# STM32H7R register map
File version: 1.4
CPU: CM7 r0p1, little endian, MPU, FPU, 4 interrupt priority bits
Registers are 32-bit, read-write, reset 0x0 unless marked. A register's access mark holds for its fields unless they carry their own. Offsets are from the block's base; [hi:lo] are bit positions; {n}, {i} and the like mark numbered series; 'fields as' and 'values as' point back to an identical list; <NAME> marks a mode.

## RCC (part 1 of 2) — RCC register block
Base 0x58024400
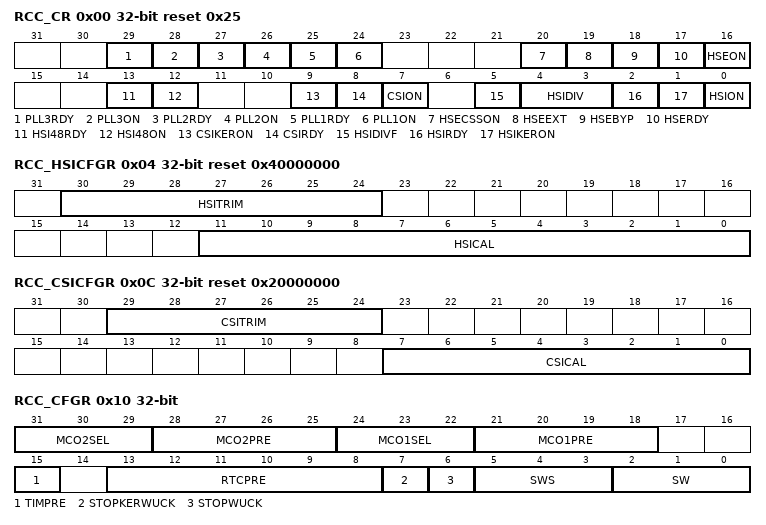
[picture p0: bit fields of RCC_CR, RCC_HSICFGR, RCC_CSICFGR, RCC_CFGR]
0x00 RCC_CR reset 0x25 — RCC source control register
  [29] PLL3RDY ro — PLL3 clock ready flag
    0=PLL3 unlocked (default after reset); 1=PLL3 locked
  [28] PLL3ON — PLL3 enable
    0=PLL3 OFF (default after reset); 1=PLL3 ON
  [27] PLL2RDY ro — PLL2 clock ready flag
    0=PLL2 unlocked (default after reset); 1=PLL2 locked
  [26] PLL2ON — PLL2 enable
    0=PLL2 OFF (default after reset); 1=PLL2 ON
  [25] PLL1RDY ro — PLL1 clock ready flag
    0=PLL1 unlocked (default after reset); 1=PLL1 locked
  [24] PLL1ON — PLL1 enable
    0=PLL1 OFF (default after reset); 1=PLL1 ON
  [20] HSECSSON — HSE clock security system enable
    0=CSS on HSE OFF (clock detector OFF) (default after reset); 1=CSS on HSE ON (clock detector ON if the HSE oscillator is stable, OFF if not)
  [19] HSEEXT — external high speed clock type in Bypass mode
    0=HSE in analog mode (default after reset); 1=HSE in digital mode
  [18] HSEBYP — HSE clock bypass
    0=HSE oscillator not bypassed (default after reset); 1=HSE oscillator bypassed with an external clock
  [17] HSERDY ro — HSE clock ready flag
    0=HSE clock is not ready (default after reset); 1=HSE clock is ready
  [16] HSEON — HSE clock enable
    0=HSE is OFF (default after reset); 1=HSE is ON
  [13] HSI48RDY ro — HSI48 clock ready flag
    0=HSI48 clock is not ready (default after reset); 1=HSI48 clock is ready
  [12] HSI48ON — HSI48 clock enable
    0=HSI48 is OFF (default after reset); 1=HSI48 is ON
  [9] CSIKERON — CSI clock enable in Stop mode
    0=no effect on CSI (default after reset); 1=CSI is forced to ON even in Stop mode
  [8] CSIRDY ro — CSI clock ready flag
    0=CSI clock is not ready (default after reset); 1=CSI clock is ready
  [7] CSION — CSI clock enable
    0=CSI is OFF (default after reset); 1=CSI is ON
  [5] HSIDIVF ro — HSI divider flag
    0=new division ratio not yet propagated to hsi(_ker)_ck (default after reset); 1=hsi(_ker)_ck clock frequency reflects the new HSIDIV value (default register value when the
  [4:3] HSIDIV — HSI clock divider
    0=division by 1, hsi(_ker)_ck = 64 MHz (default after reset); 1=division by 2, hsi(_ker)_ck = 32 MHz; 2=division by 4, hsi(_ker)_ck = 16 MHz; 3=division by 8, hsi(_ker)_ck = 8 MHz
  [2] HSIRDY ro — HSI clock ready flag
    0=HSI clock is not ready (default after reset); 1=HSI clock is ready
  [1] HSIKERON — HSI clock enable in Stop mode
    0=no effect on HSI (default after reset); 1=HSI is forced to ON even in Stop mode
  [0] HSION — HSI clock enable
    0=HSI is OFF; 1=HSI is ON (default after reset)
0x04 RCC_HSICFGR reset 0x40000000 (reset mask 0xFFFFF000) — RCC HSI calibration register
  [30:24] HSITRIM — HSI clock trimming
  [11:0] HSICAL ro — HSI clock calibration
0x08 RCC_CRRCR ro (reset mask 0xFFFFF000) — RCC clock recovery RC register
  [9:0] HSI48CAL — Internal RC 48 MHz clock calibration
0x0C RCC_CSICFGR reset 0x20000000 (reset mask 0xFFFFF000) — RCC CSI calibration register
  [29:24] CSITRIM — CSI clock trimming
  [7:0] CSICAL ro — CSI clock calibration
0x10 RCC_CFGR — RCC clock configuration register
  [31:29] MCO2SEL — microcontroller clock output 2
    0=system clock selected (sys_ck) (default after reset); 1=PLL2 oscillator clock selected (pll2_p_ck); 2=HSE clock selected (hse_ck); 3=PLL1 clock selected (pll1_p_ck); 4=CSI clock selected (csi_ck); 5=LSI clock selected (lsi_ck)
  [28:25] MCO2PRE — MCO2 prescaler
    0=prescaler disabled (default after reset); 1=division by 1 (bypass); 2=division by 2; 3=division by 3; 4=division by 4; 15=division by 15
  [24:22] MCO1SEL — Microcontroller clock output 1
    0=HSI clock selected (hsi_ck) (default after reset); 1=LSE oscillator clock selected (lse_ck); 2=HSE clock selected (hse_ck); 3=PLL1 clock selected (pll1_q_ck); 4=HSI48 clock selected (hsi48_ck)
  [21:18] MCO1PRE — MCO1 prescaler
    values as MCO2PRE
  [15] TIMPRE — timers clocks prescaler selection
    0=The timers kernel clock is equal to rcc_hclk1 if CDPPREx is corresponding to division by 1 or 2, else it is equal to 2 x F<sub>rcc_pclkx_d2 </sub>(default after reset); 1=The timers kernel clock is equal to rcc_hclk1 if CDPPREx is corresponding to division by 1, 2
  [13:8] RTCPRE — HSE division factor for RTC clock
    0=no clock (default after reset); 1=no clock; 2=HSE/2; 3=HSE/3; 4=HSE/4; 62=HSE/62; 63=HSE/63
  [7] STOPKERWUCK — kernel clock selection after a wake up from system Stop
    0=HSI selected as wake up clock from system Stop (default after reset); 1=CSI selected as wake up clock from system Stop
  [6] STOPWUCK — system clock selection after a wake up from system Stop
    values as STOPKERWUCK
  [5:3] SWS ro — system clock switch status
    0=HSI used as system clock (hsi_ck) (default after reset); 1=CSI used as system clock (csi_ck); 2=HSE used as system clock (hse_ck); 3=PLL1 used as system clock (pll1_p_ck)
  [2:0] SW — system clock switch
    0=HSI selected as system clock (hsi_ck) (default after reset); 1=CSI selected as system clock (csi_ck); 2=HSE selected as system clock (hse_ck); 3=PLL1 selected as system clock (pll1_p_ck)
0x18 RCC_CDCFGR — RCC CPU domain clock configuration register
  [3:0] CPRE — CPU domain core prescaler
    8=sys_ck divided by 2; 9=sys_ck divided by 4; 10=sys_ck divided by 8; 11=sys_ck divided by 16; 12=sys_ck divided by 64; 13=sys_ck divided by 128; 14=sys_ck divided by 256; 15=sys_ck divided by 512
0x1C RCC_BMCFGR — RCC AHB clock configuration register
  [3:0] BMPRE — Bus matrix clock prescaler
    8=sys_bus_ck = sys_cpu_ck / 2; 9=sys_bus_ck= sys_cpu_ck / 4; 10=sys_bus_ck = sys_cpu_ck / 8; 11=sys_bus_ck = sys_cpu_ck / 16; 12=sys_bus_ck = sys_cpu_ck / 64; 13=sys_bus_ck = sys_cpu_ck / 128; 14=sys_bus_ck = sys_cpu_ck / 256; 15=sys_bus_ck = sys_cpu_ck / 512
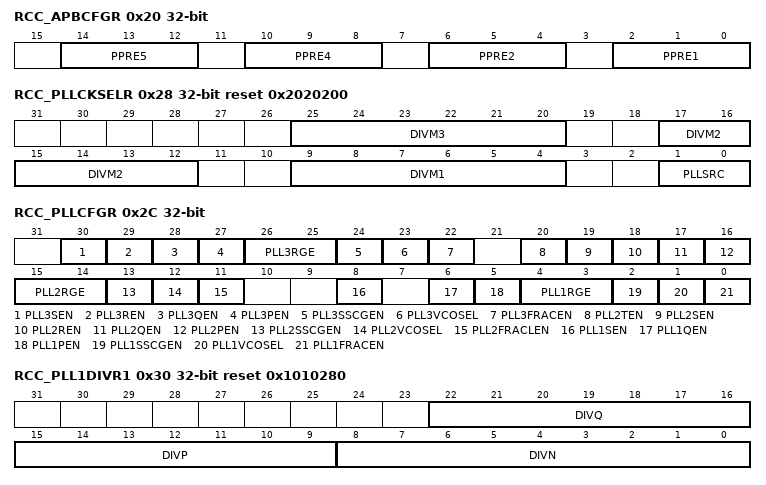
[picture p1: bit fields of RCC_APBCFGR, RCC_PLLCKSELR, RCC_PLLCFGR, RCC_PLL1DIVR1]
0x20 RCC_APBCFGR — RCC APB clocks configuration register
  [14:12] PPRE5 — CPU domain APB5 prescaler
    4=rcc_pclk5 = sys_bus_ck / 2; 5=rcc_pclk5 = sys_bus_ck / 4; 6=rcc_pclk5 = sys_bus_ck / 8; 7=rcc_pclk5 = sys_bus_ck / 16
  [10:8] PPRE4 — CPU domain APB4 prescaler
    4=rcc_pclk4 = sys_bus_ck / 2; 5=rcc_pclk4 = sys_bus_ck / 4; 6=rcc_pclk4 = sys_bus_ck / 8; 7=rcc_pclk4 = sys_bus_ck / 16
  [6:4] PPRE2 — CPU domain APB2 prescaler
    4=rcc_pclk2 = sys_bus_ck / 2; 5=rcc_pclk2 = sys_bus_ck / 4; 6=rcc_pclk2 = sys_bus_ck / 8; 7=rcc_pclk2 = sys_bus_ck / 16
  [2:0] PPRE1 — CPU domain APB1 prescaler
    4=rcc_pclk1 = sys_bus_ck / 2; 5=rcc_pclk1 = sys_bus_ck / 4; 6=rcc_pclk1 = sys_bus_ck / 8; 7=rcc_pclk1 = sys_bus_ck / 16
0x28 RCC_PLLCKSELR reset 0x2020200 — RCC PLLs clock source selection register
  [25:20] DIVM3 — prescaler for PLL3
    0=prescaler disabled; 1=division by 1 (bypass); 2=division by 2; 3=division by 3; 32=division by 32 (default after reset); 63=division by 63
  [17:12] DIVM2 — prescaler for PLL2
    values as DIVM3
  [9:4] DIVM1 — prescaler for PLL1
    values as DIVM3
  [1:0] PLLSRC — DIVMx and PLLs clock source selection
    0=HSI selected as PLL clock (hsi_ck) (default after reset); 1=CSI selected as PLL clock (csi_ck); 2=HSE selected as PLL clock (hse_ck); 3=no clock send to DIVMx divider and PLLs
0x2C RCC_PLLCFGR — RCC PLLs configuration register
  [30] PLL3SEN — PLL3 DIVS divider output enable
    0=pll3_s_ck output disabled (default after reset); 1=pll3_s_ck output enabled
  [29] PLL3REN — PLL3 DIVR divider output enable
    0=pll3_r_ck output disabled (default after reset); 1=pll3_r_ck output enabled
  [28] PLL3QEN — PLL3 DIVQ divider output enable
    0=pll3_q_ck output disabled (default after reset); 1=pll3_q_ck output enabled
  [27] PLL3PEN — PLL3 DIVP divider output enable
    0=pll3_p_ck output disabled (default after reset); 1=pll3_p_ck output enabled
  [26:25] PLL3RGE — PLL3 input frequency range
    0=PLL3 input (ref3_ck) clock range frequency between 1 and 2 MHz (default after reset); 1=PLL3 input (ref3_ck) clock range frequency between 2 and 4 MHz; 2=PLL3 input (ref3_ck) clock range frequency between 4 and 8 MHz; 3=PLL3 input (ref3_ck) clock range frequency between 8 and 16 MHz
  [24] PLL3SSCGEN — PLL3 SSCG enable
    0=SSCG disabled (default after reset); 1=SSCG enabled
  [23] PLL3VCOSEL — PLL3 VCO selection
    0=VCOH selected (default after reset); 1=VCOL selected
  [22] PLL3FRACEN — PLL3 fractional latch enable
  [20] PLL2TEN — PLL2 DIVT divider output enable
    0=pll2_t_ck output disabled (default after reset); 1=pll2_t_ck output enabled
  [19] PLL2SEN — PLL2 DIVS divider output enable
    0=pll2_s_ck output disabled (default after reset); 1=pll2_s_ck output enabled
  [18] PLL2REN — PLL2 DIVR divider output enable
    0=pll2_r_ck output disabled (default after reset); 1=pll2_r_ck output enabled
  [17] PLL2QEN — PLL2 DIVQ divider output enable
    0=pll2_q_ck output disabled (default after reset); 1=pll2_q_ck output enabled
  [16] PLL2PEN — PLL2 DIVP divider output enable
    0=pll2_p_ck output disabled (default after reset); 1=pll2_p_ck output enabled
  [15:14] PLL2RGE — PLL2 input frequency range
    0=PLL3 input (ref2_ck) clock range frequency between 1 and 2 MHz (default after reset); 1=PLL3 input (ref2_ck) clock range frequency between 2 and 4 MHz; 2=PLL3 input (ref2_ck) clock range frequency between 4 and 8 MHz; 3=PLL3 input (ref2_ck) clock range frequency between 8 and 16 MHz
  [13] PLL2SSCGEN — PLL2 SSCG enable
    0=SSCG disabled (default after reset); 1=SSCG enabled
  [12] PLL2VCOSEL — PLL2 VCO selection
    0=VCOH selected (default after reset); 1=VCOL selected
  [11] PLL2FRACLEN — PLL2 fractional latch enable
  [8] PLL1SEN — PLL1 DIVS divider output enable
    0=pll1_s_ck output disabled (default after reset); 1=pll1_s_ck output enabled
  [6] PLL1QEN — PLL1 DIVQ divider output enable
    0=pll1_q_ck output disabled (default after reset); 1=pll1_q_ck output enabled
  [5] PLL1PEN — PLL1 DIVP divider output enable
    0=pll1_p_ck output disabled (default after reset); 1=pll1_p_ck output enabled
  [4:3] PLL1RGE — PLL1 input frequency range
    0=PLL1 input (ref1_ck) clock range frequency between 1 and 2 MHz (default after reset); 1=PLL1 input (ref1_ck) clock range frequency between 2 and 4 MHz; 2=PLL1 input (ref1_ck) clock range frequency between 4 and 8 MHz; 3=PLL1 input (ref1_ck) clock range frequency between 8 and 16 MHz
  [2] PLL1SSCGEN — PLL1 SSCG enable
    0=SSCG disabled (default after reset); 1=SSCG enabled
  [1] PLL1VCOSEL — PLL1 VCO selection
    0=VCOH selected (default after reset); 1=VCOL selected
  [0] PLL1FRACEN — PLL1 fractional latch enable
0x30 RCC_PLL1DIVR1 reset 0x1010280 — RCC PLL1 dividers configuration register 1
  [22:16] DIVQ — PLL1 DIVQ division factor
    0=pll1_q_ck = vco1_ck; 1=pll1_q_ck = vco1_ck / 2 (default after reset); 2=pll1_q_ck = vco1_ck / 3; 3=pll1_q_ck = vco1_ck / 4; 127=pll1_q_ck = vco1_ck / 128
  [15:9] DIVP — PLL1 DIVP division factor
    0=pll1_p_ck = vco1_ck; 1=pll1_p_ck = vco1_ck / 2 (default after reset); 2=not allowed; 3=pll1_p_ck = vco1_ck / 4; 127=pll1_p_ck = vco1_ck / 128
  [8:0] DIVN — multiplication factor for PLL1 VCO
    6=wrong configuration; 7=DIVN = 8; 128=DIVN = 129 (default after reset); 0x1A3=DIVN = 420
{0x2C+8i} RCC_PLL{i}FRACR (i=1..3) — RCC PLL{i} fractional divider register
  [15:3] FRACN — fractional part of the multiplication factor for PLL{i} VCO
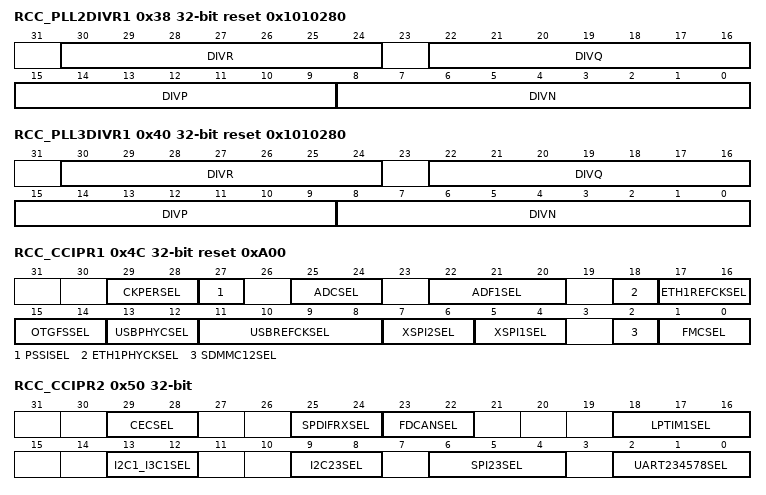
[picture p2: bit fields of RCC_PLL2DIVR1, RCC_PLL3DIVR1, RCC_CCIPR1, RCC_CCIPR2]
0x38 RCC_PLL2DIVR1 reset 0x1010280 — RCC PLL2 dividers configuration register 1
  [30:24] DIVR — PLL2 DIVR division factor
    0=pll2_r_ck = vco2_ck; 1=pll2_r_ck = vco2_ck / 2 (default after reset); 2=pll2_r_ck = vco2_ck / 3; 3=pll2_r_ck = vco2_ck / 4; 127=pll2_r_ck = vco2_ck / 128
  [22:16] DIVQ — PLL2 DIVQ division factor
    0=pll2_q_ck = vco2_ck; 1=pll2_q_ck = vco2_ck / 2 (default after reset); 2=pll2_q_ck = vco2_ck / 3; 3=pll2_q_ck = vco2_ck / 4; 127=pll2_q_ck = vco2_ck / 128
  [15:9] DIVP — PLL2 DIVP division factor
    0=pll2_p_ck = vco2_ck; 1=pll2_p_ck = vco2_ck / 2 (default after reset); 2=pll2_p_ck = vco2_ck / 3; 3=pll2_p_ck = vco2_ck / 4; 127=pll2_p_ck = vco2_ck / 128
  [8:0] DIVN — multiplication factor for PLL2 VCO
    values as RCC_PLL1DIVR1.DIVN
0x40 RCC_PLL3DIVR1 reset 0x1010280 — RCC PLL3 dividers configuration register 1
  [30:24] DIVR — PLL3 DIVR division factor
    0=pll3_r_ck = vco3_ck; 1=pll3_r_ck = vco3_ck / 2 (default after reset); 2=pll3_r_ck = vco3_ck / 3; 3=pll3_r_ck = vco3_ck / 4; 127=pll3_r_ck = vco3_ck / 128
  [22:16] DIVQ — PLL3 DIVQ division factor
    0=pll3_q_ck = vco3_ck; 1=pll3_q_ck = vco3_ck / 2 (default after reset); 2=pll3_q_ck = vco3_ck / 3; 3=pll3_q_ck = vco3_ck / 4; 127=pll3_q_ck = vco3_ck / 128
  [15:9] DIVP — PLL3 DIVP division factor
    0=pll3_p_ck = vco3_ck; 1=pll3_p_ck = vco3_ck / 2 (default after reset); 2=pll3_p_ck = vco3_ck / 3; 3=pll3_p_ck = vco3_ck / 4; 127=pll3_p_ck = vco3_ck / 128
  [8:0] DIVN — Multiplication factor for PLL3 VCO
    values as RCC_PLL1DIVR1.DIVN
0x4C RCC_CCIPR1 reset 0xA00 — RCC AHB peripheral kernel clock selection register
  [29:28] CKPERSEL — per_ck clock source selection
    0=hsi_ker_ck selected as per_ck clock (default after reset); 1=csi_ker_ck selected as per_ck clock; 2=hse_ker_ck selected as per_ck clock
  [27] PSSISEL — PSSI kernel clock source selection
    0=pll3_r_ck selected as kernel peripheral clock (default after reset); 1=per_ck selected as kernel peripheral clock
  [25:24] ADCSEL — SAR ADC kernel clock source selection
    0=pll2_p_ck selected as kernel peripheral clock (default after reset); 1=pll3_r_ck selected as kernel peripheral clock; 2=per_ck selected as kernel peripheral clock
  [22:20] ADF1SEL — ADF kernel clock source selection
    0=hclk1 selected as ADF kernel clock (default after reset); 1=pll2_p_ck selected as ADF kernel clock
  [18] ETH1PHYCKSEL — Clock source selection for external Ethernet PHY
    0=hse_ker_ck selected as clock source (default after reset); 1=pll3_s_ck selected clock source
  [17:16] ETH1REFCKSEL — Ethernet reference clock source selection
    0=PAD ETH_RMII_REF_CLK selected as kernel peripheral clock (default after reset); 1=hse_ker_ck selected as kernel peripheral clock; 2=eth_clk_fb selected as kernel peripheral clock
  [15:14] OTGFSSEL — OTGFS kernel clock source selection
    0=hsi48_ker_ck (default after reset); 1=pll3_q_ck; 2=hse_ker_ck; 3=clk48mohci
  [13:12] USBPHYCSEL — USBPHYC kernel clock source selection
    0=hse_ker_ck (default after reset); 1=hse_ker_ck / 2; 2=pll3_q_ck
  [11:8] USBREFCKSEL — USBPHYC kernel clock frequency selection
    3=The kernel clock frequency provided to the USBPHYC is 16 MHz; 8=The kernel clock frequency provided to the USBPHYC is 19; 9=The kernel clock frequency provided to the USBPHYC is 20MHz; 10=The kernel clock frequency provided to the USBPHYC is 24 MHz (default after reset); 14=The kernel clock frequency provided to the USBPHYC is 26 MHz; 11=The kernel clock frequency provided to the USBPHYC is 32 MHz
  [7:6] XSPI2SEL — XSPI2 kernel clock source selection
    0=hclk5 selected as kernel peripheral clock (default after reset); 1=pll2_s_ck selected as kernel peripheral clock
  [5:4] XSPI1SEL — XSPI1 kernel clock source selection
    values as XSPI2SEL
  [2] SDMMC12SEL — SDMMC1 and SDMMC2 kernel clock source selection
    0=pll2_s_ck selected as kernel peripheral clock (default after reset); 1=pll2_t_ck selected as kernel peripheral clock
  [1:0] FMCSEL — FMC kernel clock source selection
    0=hclk5 selected as kernel peripheral clock (default after reset); 1=pll1_q_ck selected as kernel peripheral clock; 2=pll2_r_ck selected as kernel peripheral clock; 3=hsi_ker_ck selected as kernel peripheral clock
0x50 RCC_CCIPR2 — RCC APB1 peripherals kernel clock selection register
  [29:28] CECSEL — HDMI-CEC kernel clock source selection
    0=lse_ck selected as kernel clock (default after reset); 1=lsi_ck selected as kernel clock; 2=csi_ker_ck divided by 122 selected as kernel clock
  [25:24] SPDIFRXSEL — SPDIFRX kernel clock source selection
    0=pll1_q_ck selected as SPDIFRX kernel clock (default after reset); 1=pll2_r_ck selected as SPDIFRX kernel clock; 2=pll3_r_ck selected as SPDIFRX kernel clock; 3=hsi_ker_ck selected as SPDIFRX kernel clock
  [23:22] FDCANSEL — FDCAN kernel clock source selection
    0=hse_ker_ck selected as FDCAN kernel clock (default after reset); 1=pll1_q_ck selected as FDCAN kernel clock; 2=pll2_p_ck selected as FDCAN kernel clock
  [18:16] LPTIM1SEL — LPTIM1 kernel clock source selection
    0=pclk1 selected as kernel peripheral clock (default after reset); 1=pll2_p_ck selected as kernel peripheral clock; 2=pll3_r_ck selected as kernel peripheral clock; 3=lse_ck selected as kernel peripheral clock; 4=lsi_ck selected as kernel peripheral clock; 5=per_ck selected as kernel peripheral clock
  [13:12] I2C1_I3C1SEL — I2C1 or I3C1 kernel clock source selection
    0=pclk1 selected as kernel peripheral clock (default after reset); 1=pll3_r_ck selected as kernel peripheral clock; 2=hsi_ker_ck selected as kernel peripheral clock; 3=csi_ker_ck selected as kernel peripheral clock
  [9:8] I2C23SEL — I2C2, I2C3 kernel clock source selection
    0=pclk1 selected as kernel clock (default after reset); 1=pll3_r_ck selected as kernel clock; 2=hsi_ker_ck selected as kernel clock; 3=csi_ker_ck selected as kernel clock
  [6:4] SPI23SEL — SPI/I2S2 and SPI/I2S3 kernel clock source selection
    0=pll1_q_ck selected as kernel clock (default after reset); 1=pll2_p_ck selected as kernel clock; 2=pll3_p_ck selected as kernel clock; 3=I2S_CKIN selected as kernel clock; 4=per_ck selected as kernel clock
  [2:0] UART234578SEL — USART2,3, UART4,5,7,8 (APB1) kernel clock source selection
    0=pclk1 selected as kernel clock (default after reset); 1=pll2_q_ck selected as kernel clock; 2=pll3_q_ck selected as kernel clock; 3=hsi_ker_ck selected as kernel clock; 4=csi_ker_ck selected as kernel clock; 5=lse_ck selected as kernel clock
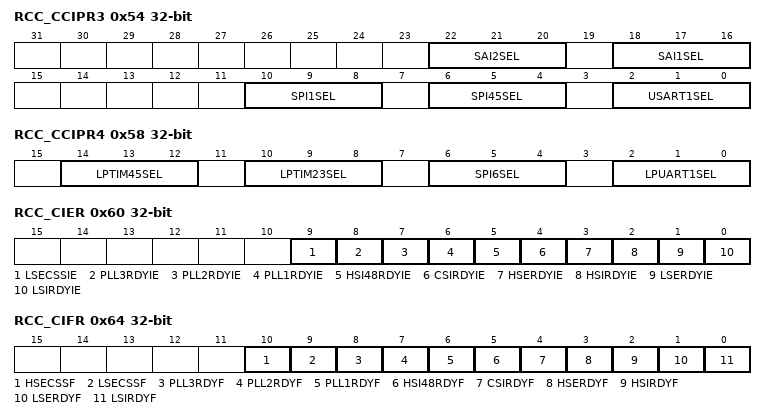
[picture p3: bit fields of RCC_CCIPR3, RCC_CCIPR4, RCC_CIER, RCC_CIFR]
0x54 RCC_CCIPR3 — RCC APB2 peripherals kernel clock selection register
  [22:20] SAI2SEL — SAI2 kernel clock source selection
    0=pll1_q_ck selected as SAI2 kernel clock (default after reset); 1=pll2_p_ck selected as SAI2 kernel clock; 2=pll3_p_ck selected as SAI2 kernel clock; 3=I2S_CKIN selected as SAI2 kernel clock; 4=per_ck selected as SAI2 kernel clock; 5=spdifrx_symb_ck selected as SAI2 kernel clock
  [18:16] SAI1SEL — SAI1 kernel clock source selection
    0=pll1_q_ck selected as SAI1 kernel clock (default after reset); 1=pll2_p_ck selected as SAI1 kernel clock; 2=pll3_p_ck selected as SAI1 kernel clock; 3=I2S_CKIN selected as SAI1 kernel clock; 4=per_ck selected as SAI1 kernel clock
  [10:8] SPI1SEL — SPI/I2S1 kernel clock source selection
    0=pll1_q_ck selected as SPI/I2S1 and 7 kernel clock (default after reset); 1=pll2_p_ck selected as SPI/I2S1 and 7 kernel clock; 2=pll3_p_ck selected as SPI/I2S1 and 7 kernel clock; 3=I2S_CKIN selected as SPI/I2S1 and 7 kernel clock; 4=per_ck selected as SPI/I2S1,and 7 kernel clock
  [6:4] SPI45SEL — SPI4 and 5 kernel clock source selection
    0=pclk2 selected as kernel clock (default after reset); 1=pll2_q_ck is selected as kernel clock; 2=pll3_q_ck is selected as kernel clock; 3=hsi_ker_ck is selected as kernel clock; 4=csi_ker_ck is selected as kernel clock; 5=hse_ker_ck is selected as kernel clock
  [2:0] USART1SEL — USART1 kernel clock source selection
    0=pclk2 selected as kernel clock (default after reset); 1=pll2_q_ck selected as kernel clock; 2=pll3_q_ck selected as kernel clock; 3=hsi_ker_ck selected as kernel clock; 4=csi_ker_ck selected as kernel clock; 5=lse_ck selected as kernel clock
0x58 RCC_CCIPR4 — RCC APB4,5 peripherals kernel clock selection register
  [14:12] LPTIM45SEL — LPTIM4, and LPTIM5 kernel clock source selection
    0=pclk4 selected as kernel peripheral clock (default after reset); 1=pll2_p_ck selected as kernel peripheral clock; 2=pll3_r_ck selected as kernel peripheral clock; 3=lse_ck selected as kernel peripheral clock; 4=lsi_ck selected as kernel peripheral clock; 5=per_ck selected as kernel peripheral clock
  [10:8] LPTIM23SEL — LPTIM2 and LPTIM3 kernel clock source selection
    values as LPTIM45SEL
  [6:4] SPI6SEL — SPI/I2S6 kernel clock source selection
    0=pclk4 selected as kernel peripheral clock (default after reset); 1=pll2_q_ck selected as kernel peripheral clock; 2=pll3_q_ck selected as kernel peripheral clock; 3=hsi_ker_ck selected as kernel peripheral clock; 4=csi_ker_ck selected as kernel peripheral clock; 5=hse_ker_ck selected as kernel peripheral clock
  [2:0] LPUART1SEL — LPUART1 kernel clock source selection
    0=pclk4 selected as kernel peripheral clock (default after reset); 1=pll2_q_ck selected as kernel peripheral clock; 2=pll3_q_ck selected as kernel peripheral clock; 3=hsi_ker_ck selected as kernel peripheral clock; 4=csi_ker_ck selected as kernel peripheral clock; 5=lse_ck selected as kernel peripheral clock
0x60 RCC_CIER — RCC clock source interrupt enable register
  [9] LSECSSIE — LSE clock security system interrupt enable
    0=LSE CSS interrupt disabled (default after reset); 1=LSE CSS interrupt enabled
  [8] PLL3RDYIE — PLL3 ready interrupt enable
    0=PLL3 lock interrupt disabled (default after reset); 1=PLL3 lock interrupt enabled
  [7] PLL2RDYIE — PLL2 ready interrupt enable
    0=PLL2 lock interrupt disabled (default after reset); 1=PLL2 lock interrupt enabled
  [6] PLL1RDYIE — PLL1 ready interrupt enable
    0=PLL1 lock interrupt disabled (default after reset); 1=PLL1 lock interrupt enabled
  [5] HSI48RDYIE — HSI48 ready interrupt enable
    0=HSI48 ready interrupt disabled (default after reset); 1=HSI48 ready interrupt enabled
  [4] CSIRDYIE — CSI ready interrupt enable
    0=CSI ready interrupt disabled (default after reset); 1=CSI ready interrupt enabled
  [3] HSERDYIE — HSE ready interrupt enable
    0=HSE ready interrupt disabled (default after reset); 1=HSE ready interrupt enabled
  [2] HSIRDYIE — HSI ready interrupt enable
    0=HSI ready interrupt disabled (default after reset); 1=HSI ready interrupt enabled
  [1] LSERDYIE — LSE ready interrupt enable
    0=LSE ready interrupt disabled (default after reset); 1=LSE ready interrupt enabled
  [0] LSIRDYIE — LSI ready interrupt enable
    0=LSI ready interrupt disabled (default after reset); 1=LSI ready interrupt enabled
0x64 RCC_CIFR ro — RCC clock source interrupt flag register
  [10] HSECSSF — HSE clock security system interrupt flag
    0=no clock security interrupt caused by HSE clock failure (default after reset); 1=clock security interrupt caused by HSE clock failure
  [9] LSECSSF — LSE clock security system interrupt flag
    0=no failure detected on the external 32 kHz oscillator (default after reset); 1=failure detected on the external 32 kHz oscillator
  [8] PLL3RDYF — PLL3 ready interrupt flag
    0=no clock ready interrupt caused by PLL3 lock (default after reset); 1=clock ready interrupt caused by PLL3 lock
  [7] PLL2RDYF — PLL2 ready interrupt flag
    0=no clock ready interrupt caused by PLL2 lock (default after reset); 1=clock ready interrupt caused by PLL2 lock
  [6] PLL1RDYF — PLL1 ready interrupt flag
    0=no clock ready interrupt caused by PLL1 lock (default after reset); 1=clock ready interrupt caused by PLL1 lock
  [5] HSI48RDYF — HSI48 ready interrupt flag
    0=no clock ready interrupt caused by the HSI48 oscillator (default after reset); 1=clock ready interrupt caused by the HSI48 oscillator
  [4] CSIRDYF — CSI ready interrupt flag
    0=no clock ready interrupt caused by the CSI (default after reset); 1=clock ready interrupt caused by the CSI
  [3] HSERDYF — HSE ready interrupt flag
    0=no clock ready interrupt caused by the HSE (default after reset); 1=clock ready interrupt caused by the HSE
  [2] HSIRDYF — HSI ready interrupt flag
    0=no clock ready interrupt caused by the HSI (default after reset); 1=clock ready interrupt caused by the HSI
  [1] LSERDYF — LSE ready interrupt flag
    0=no clock ready interrupt caused by the LSE (default after reset); 1=clock ready interrupt caused by the LSE
  [0] LSIRDYF — LSI ready interrupt flag
    0=no clock ready interrupt caused by the LSI (default after reset); 1=clock ready interrupt caused by the LSI
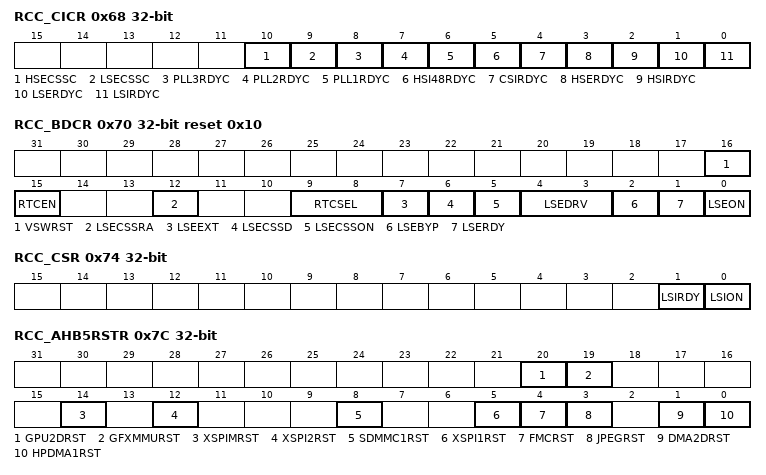
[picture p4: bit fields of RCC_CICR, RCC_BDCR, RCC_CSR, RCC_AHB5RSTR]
0x68 RCC_CICR — RCC clock source interrupt clear register
  [10] HSECSSC — HSE clock security system interrupt clear
    0=HSECSSF no effect (default after reset); 1=HSECSSF cleared
  [9] LSECSSC — LSE clock security system interrupt clear
    0=LSECSSF no effect (default after reset); 1=LSECSSF cleared
  [8] PLL3RDYC — PLL3 ready interrupt clear
    0=PLL3RDYF no effect (default after reset); 1=PLL3RDYF cleared
  [7] PLL2RDYC — PLL2 ready interrupt clear
    0=PLL2RDYF no effect (default after reset); 1=PLL2RDYF cleared
  [6] PLL1RDYC — PLL1 ready interrupt clear
    0=PLL1RDYF no effect (default after reset); 1=PLL1RDYF cleared
  [5] HSI48RDYC — HSI48 ready interrupt clear
    0=HSI48RDYF no effect (default after reset); 1=HSI48RDYF cleared
  [4] CSIRDYC — CSI ready interrupt clear
    0=CSIRDYF no effect (default after reset); 1=CSIRDYF cleared
  [3] HSERDYC — HSE ready interrupt clear
    0=HSERDYF no effect (default after reset); 1=HSERDYF cleared
  [2] HSIRDYC — HSI ready interrupt clear
    0=HSIRDYF no effect (default after reset); 1=HSIRDYF cleared
  [1] LSERDYC — LSE ready interrupt clear
    0=LSERDYF no effect (default after reset); 1=LSERDYF cleared
  [0] LSIRDYC — LSI ready interrupt clear
    0=LSIRDYF no effect (default after reset); 1=LSIRDYF cleared
0x70 RCC_BDCR rw-once reset 0x10 — RCC Backup domain control register
  [16] VSWRST rw — VSwitch domain software reset
    0=reset not activated (default after Backup domain reset); 1=generates a reset pulse, resetting the entire VSW domain
  [15] RTCEN rw — RTC clock enable
    0=rtc_ck disabled (default after Backup domain reset); 1=rtc_ck enabled
  [12] LSECSSRA rw — Re-Arm the LSECSS function
    0=Writing 0 has no effect (default after Backup domain reset); 1=Writing 1 generates a re-arm pulse for the LSECSS function
  [9:8] RTCSEL — RTC clock source selection
    0=no clock (default after Backup domain reset); 1=LSE selected as RTC clock; 2=LSI selected as RTC clock; 3=HSE divided by RTCPRE value selected as RTC clock
  [7] LSEEXT rw — low-speed external clock type in Bypass mode
    0=LSE in analog mode (default after Backup domain reset); 1=LSE in digital mode (do not use if RTC is active)
  [6] LSECSSD ro — LSE clock security system failure detection
    0=no failure detected on 32 kHz oscillator (default after Backup domain reset); 1=failure detected on 32 kHz oscillator
  [5] LSECSSON rw — LSE clock security system enable
    0=CSS on 32 kHz oscillator OFF (default after Backup domain reset); 1=CSS on 32 kHz oscillator ON
  [4:3] LSEDRV rw — LSE oscillator driving capability
    0=lowest drive; 1=medium-low drive; 2=medium-high drive (default after backup domain if LSEON=0); 3=highest drive
  [2] LSEBYP rw — LSE oscillator bypass
    0=LSE oscillator not bypassed (default after Backup domain reset); 1=LSE oscillator bypassed
  [1] LSERDY ro — LSE oscillator ready
    0=LSE oscillator not ready (default after Backup domain reset); 1=LSE oscillator ready
  [0] LSEON rw — LSE oscillator enabled
    0=LSE oscillator OFF (default after Backup domain reset); 1=LSE oscillator ON
0x74 RCC_CSR — RCC clock control and status register
  [1] LSIRDY ro — LSI oscillator ready
    0=LSI clock is not ready (default after reset); 1=LSI clock is ready
  [0] LSION — LSI oscillator enable
    0=LSI is OFF (default after reset); 1=LSI is ON
0x7C RCC_AHB5RSTR — RCC AHB5 peripheral reset register
  [all] fields
    0=reset is released (default after reset); 1=reset is asserted
  [20] GPU2DRST — GPU2D block reset
  [19] GFXMMURST — GFXMMU block reset
  [14] XSPIMRST — XSPIM reset
  [12] XSPI2RST — XSPI2 and MCE2 blocks reset
  [8] SDMMC1RST — SDMMC1 and DB_SDMMC1 blocks reset
  [5] XSPI1RST — XSPI1 and MCE1 blocks reset
  [4] FMCRST — FMC and MCE3 blocks reset
  [3] JPEGRST — JPEG block reset
  [1] DMA2DRST — DMA2D block reset
  [0] HPDMA1RST — HPDMA1 block reset
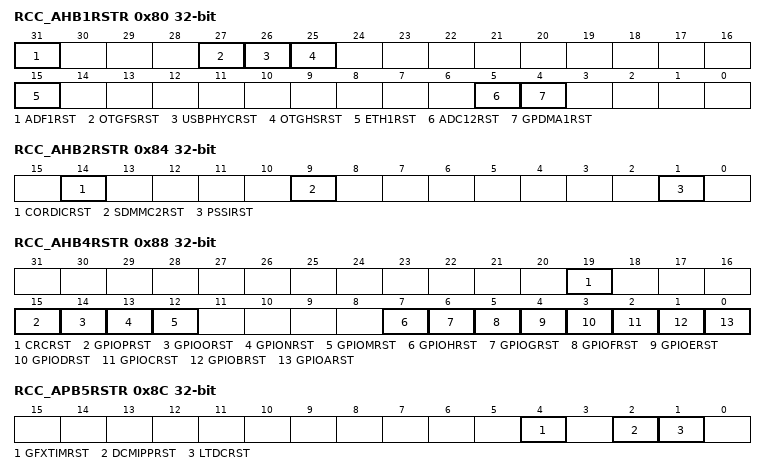
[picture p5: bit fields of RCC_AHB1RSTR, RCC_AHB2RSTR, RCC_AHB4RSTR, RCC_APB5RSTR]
0x80 RCC_AHB1RSTR — RCC AHB1 peripheral reset register
  [31] ADF1RST — ADF block reset
    0=does not reset ADF block (default after reset); 1=resets ADF block
  [27] OTGFSRST — OTGFS block reset
    0=does not reset OTGFS block (default after reset); 1=resets OTGFS block
  [26] USBPHYCRST — USBPHYC block reset
    0=does not reset USBPHYC block (default after reset); 1=resets USBPHYC block
  [25] OTGHSRST — OTGHS block reset
    0=does not reset OTGHS block (default after reset); 1=resets OTGHS block
  [15] ETH1RST — ETH1 block reset
    0=does not reset ETH1 block (default after reset); 1=resets ETH1 block
  [5] ADC12RST — ADC1 and 2 blocks reset
    0=does not reset ADC1 and 2 blocks (default after reset); 1=resets ADC1 and 2 blocks
  [4] GPDMA1RST — GPDMA1 blocks reset
    0=does not reset GPDMA1 block (default after reset); 1=resets GPDMA1 block
0x84 RCC_AHB2RSTR — RCC AHB2 peripheral reset register
  [14] CORDICRST — CORDIC reset
    0=does not reset CORDIC block (default after reset); 1=resets CORDIC block
  [9] SDMMC2RST — SDMMC2 and SDMMC2 delay blocks reset
    0=does not reset SDMMC2 and SDMMC2 delay blocks (default after reset); 1=resets SDMMC2 and SDMMC2 delay blocks
  [1] PSSIRST — PSSI block reset
    0=does not reset PSSI block (default after reset); 1=resets PSSI block
0x88 RCC_AHB4RSTR — RCC AHB4 peripheral reset register
  [19] CRCRST — CRC block reset
    0=does not reset the CRC block (default after reset); 1=resets the CRC block
  [15] GPIOPRST — GPIOP block reset
    0=does not reset the GPIOP block (default after reset); 1=resets the GPIOP block
  [14] GPIOORST — GPIOO block reset
    0=does not reset the GPIOO block (default after reset); 1=resets the GPIOO block
  [13] GPIONRST — GPION block reset
    0=does not reset the GPION block (default after reset); 1=resets the GPION block
  [12] GPIOMRST — GPIOM block reset
    0=does not reset the GPIOM block (default after reset); 1=resets the GPIOM block
  [7] GPIOHRST — GPIOH block reset
    0=does not reset the GPIOH block (default after reset); 1=resets the GPIOH block
  [6] GPIOGRST — GPIOG block reset
    0=does not reset the GPIOG block (default after reset); 1=resets the GPIOG block
  [5] GPIOFRST — GPIOF block reset
    0=does not reset the GPIOF block (default after reset); 1=resets the GPIOF block
  [4] GPIOERST — GPIOE block reset
    0=does not reset the GPIOE block (default after reset); 1=resets the GPIOE block
  [3] GPIODRST — GPIOD block reset
    0=does not reset the GPIOD block (default after reset); 1=resets the GPIOD block
  [2] GPIOCRST — GPIOC block reset
    0=does not reset the GPIOC block (default after reset); 1=resets the GPIOC block
  [1] GPIOBRST — GPIOB block reset
    0=does not reset the GPIOB block (default after reset); 1=resets the GPIOB block
  [0] GPIOARST — GPIOA block reset
    0=does not reset the GPIOA block (default after reset); 1=resets the GPIOA block
0x8C RCC_APB5RSTR — RCC APB5 peripheral reset register
  [4] GFXTIMRST — GFXTIM block reset
    0=does not reset the GFXTIM block (default after reset); 1=resets the GFXTIM block
  [2] DCMIPPRST — DCMIPP block reset
    0=does not reset the DCMIPP block (default after reset); 1=resets the DCMIPP block
  [1] LTDCRST — LTDC block reset
    0=does not reset the LTDC block (default after reset); 1=resets the LTDC block
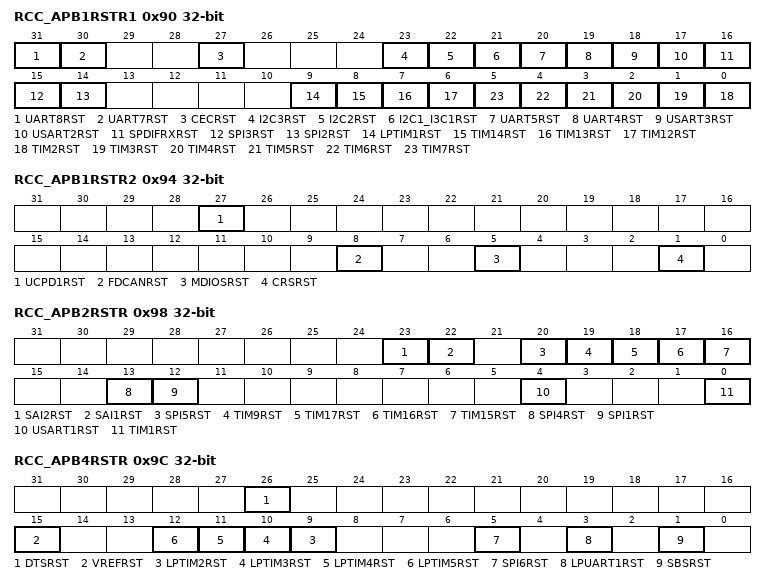
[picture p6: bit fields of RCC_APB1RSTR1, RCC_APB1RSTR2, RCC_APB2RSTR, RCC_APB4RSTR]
0x90 RCC_APB1RSTR1 — RCC APB1 peripheral reset register 1
  [31] UART8RST — UART8 block reset
    0=does not reset the UART8 block (default after reset); 1=resets the UART8 block
  [30] UART7RST — UART7 block reset
    0=does not reset the UART7 block (default after reset); 1=resets the UART7 block
  [27] CECRST — HDMI-CEC block reset
    0=does not reset the HDMI-CEC block (default after reset); 1=resets the HDMI-CEC block
  [23] I2C3RST — I2C3 block reset
    0=does not reset the I2C3 block (default after reset); 1=resets the I2C3 block
  [22] I2C2RST — I2C2 block reset
    0=does not reset the I2C2 block (default after reset); 1=resets the I2C2 block
  [21] I2C1_I3C1RST — I2C1/I3C1 block reset
    0=does not reset the I2C1/I3C1 block (default after reset); 1=resets the I2C1/I3C1 block
  [20] UART5RST — UART5 block reset
    0=does not reset the UART5 block (default after reset); 1=resets the UART5 block
  [19] UART4RST — UART4 block reset
    0=does not reset the UART4 block (default after reset); 1=resets the UART4 block
  [18] USART3RST — USART3 block reset
    0=does not reset the USART3 block (default after reset); 1=resets the USART3 block
  [17] USART2RST — USART2 block reset
    0=does not reset the USART2 block (default after reset); 1=resets the USART2 block
  [16] SPDIFRXRST — SPDIFRX block reset
    0=does not reset the SPDIFRX block (default after reset); 1=resets the SPDIFRX block
  [15] SPI3RST — SPI2S3 block reset
    0=does not reset the SPI2S3 block (default after reset); 1=resets the SPI2S3 block
  [14] SPI2RST — SPI2S2 block reset
    0=does not reset the SPI2S2 block (default after reset); 1=resets the SPI2S2 block
  [9] LPTIM1RST — LPTIM1 block reset
    0=does not reset the LPTIM1 block (default after reset); 1=resets the LPTIM1 block
  [8] TIM14RST — TIM14 block reset
    0=does not reset the TIM14 block (default after reset); 1=resets the TIM14 block
  [7] TIM13RST — TIM13 block reset
    0=does not reset the TIM13 block (default after reset); 1=resets the TIM13 block
  [6] TIM12RST — TIM12 block reset
    0=does not reset the TIM12 block (default after reset); 1=resets the TIM12 block
  [n-2] TIM{n}RST (n=2..7) — TIM{n} block reset
    0=does not reset the TIM{n} block (default after reset); 1=resets the TIM{n} block
0x94 RCC_APB1RSTR2 — RCC APB1 peripheral reset register 2
  [27] UCPD1RST — UCPD block reset
    0=does not reset the UCPD block (default after reset); 1=resets the UCPD block
  [8] FDCANRST — FDCAN block reset
    0=does not reset the FDCAN block (default after reset); 1=resets the FDCAN block
  [5] MDIOSRST — MDIOS block reset
    0=does not reset the MDIOS block (default after reset); 1=resets the MDIOS block
  [1] CRSRST — clock recovery system reset
    0=does not reset CRS (default after reset); 1=resets CRS
0x98 RCC_APB2RSTR — RCC APB2 peripheral reset register
  [23] SAI2RST — SAI2 block reset
    0=does not reset the SAI2 (default after reset); 1=resets the SAI2
  [22] SAI1RST — SAI1 block reset
    0=does not reset the SAI1 (default after reset); 1=resets the SAI1
  [20] SPI5RST — SPI5 block reset
    0=does not reset the SPI5 block (default after reset); 1=resets the SPI5 block
  [19] TIM9RST — TIM9 block reset
    0=does not reset the TIM9 block (default after reset); 1=resets the TIM9 block
  [18] TIM17RST — TIM17 block reset
    0=does not reset the TIM17 block (default after reset); 1=resets the TIM17 block
  [17] TIM16RST — TIM16 block reset
    0=does not reset the TIM16 block (default after reset); 1=resets the TIM16 block
  [16] TIM15RST — TIM15 block reset
    0=does not reset the TIM15 block (default after reset); 1=resets the TIM15 block
  [13] SPI4RST — SPI4 block reset
    0=does not reset the SPI4 block (default after reset); 1=resets the SPI4 block
  [12] SPI1RST — SPI2S1 block reset
    0=does not reset the SPI2S1 block (default after reset); 1=resets the SPI2S1 block
  [4] USART1RST — USART1 block reset
    0=does not reset the USART1 block (default after reset); 1=resets the USART1 block
  [0] TIM1RST — TIM1 block reset
    0=does not reset the TIM1 block (default after reset); 1=resets the TIM1 block
0x9C RCC_APB4RSTR — RCC APB4 peripheral reset register
  [26] DTSRST — DTS block reset
    0=does not reset the DTS block (default after reset); 1=resets the DTS block
  [15] VREFRST — VREF block reset
    0=does not reset the VREF block (default after reset); 1=resets the VREF block
  [n+7] LPTIM{n}RST (n=2..5) — LPTIM{n} block reset
    0=does not reset the LPTIM{n} block (default after reset); 1=resets the LPTIM{n} block
  [5] SPI6RST — SPI/I2S6 block reset
    0=does not reset the SPI/I2S6 block (default after reset); 1=resets the SPI/I2S6 block
  [3] LPUART1RST — LPUART1 block reset
    0=does not reset the LPUART1 block (default after reset); 1=resets the LPUART1 block
  [1] SBSRST — SBS block reset
    0=does not reset the SBS block (default after reset); 1=resets the SBS block
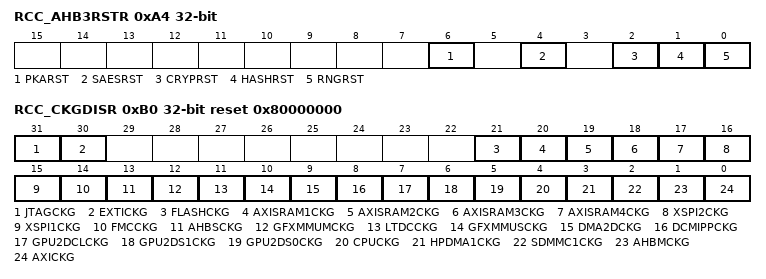
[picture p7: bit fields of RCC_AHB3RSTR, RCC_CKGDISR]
0xA4 RCC_AHB3RSTR — RCC AHB3 peripheral reset register
  [6] PKARST — PKA block reset
    0=does not reset PKA block (default after reset); 1=resets PKA block
  [4] SAESRST — SAES block reset
    0=does not reset SAES block (default after reset); 1=resets SAES block
  [2] CRYPRST — CRYP block reset
    0=does not reset CRYP block (default after reset); 1=resets CRYP block
  [1] HASHRST — HASH block reset
    0=does not reset HASH block (default after reset); 1=resets HASH block
  [0] RNGRST — random number generator block reset
    0=does not reset RNG block (default after reset); 1=resets RNG block
0xB0 RCC_CKGDISR reset 0x80000000 — RCC AXI clocks gating disable register
  [31] JTAGCKG — JTAG automatic clock gating disabling
    0=The clock gating is enabled
  [30] EXTICKG — EXTI clock gating disable
    0=The clock gating is enabled; 1=The clock gating is disabled
  [21] FLASHCKG — AXI slave Flash interface (FLIFT) clock gating disable
    values as EXTICKG
  [20] AXISRAM1CKG — AXI slave SRAM1 / error code correction (ECC) clock gating disable
    values as EXTICKG
  [19] AXISRAM2CKG — AXI slave SRAM2 clock gating disable
    values as EXTICKG
  [18] AXISRAM3CKG — AXI matrix slave SRAM3 clock gating disable
    values as EXTICKG
  [17] AXISRAM4CKG — AXI matrix slave SRAM4 clock gating disable
    values as EXTICKG
  [16] XSPI2CKG — AXI slave XSPI2 and MCE2 clock gating disable
    values as EXTICKG
  [15] XSPI1CKG — AXI slave XSPI1 and MCE1 clock gating disable
    values as EXTICKG
  [14] FMCCKG — AXI slave FMC and MCE3 clock gating disable
    values as EXTICKG
  [13] AHBSCKG — AXI slave AHB clock gating disable
    values as EXTICKG
  [12] GFXMMUMCKG — AXI master GFXMMU clock gating disable
    values as EXTICKG
  [11] LTDCCKG — AXI master LTDC clock gating disable
    values as EXTICKG
  [10] GFXMMUSCKG — AXI matrix slave GFXMMU clock gating disable
    values as EXTICKG
  [9] DMA2DCKG — AXI master DMA2D clock gating disable
    values as EXTICKG
  [8] DCMIPPCKG — AXI master DCMIPP clock gating disable
    values as EXTICKG
  [7] GPU2DCLCKG — AXI master cache GPU2D clock gating disable
    values as EXTICKG
  [6] GPU2DS1CKG — AXI master 1 GPU2D clock gating disable
    values as EXTICKG
  [5] GPU2DS0CKG — AXI master 0 GPU2D clock gating disable
    values as EXTICKG
  [4] CPUCKG — AXI master CPU clock gating disable
    values as EXTICKG
  [3] HPDMA1CKG — AXI master HPDMA1 clock gating disable
    values as EXTICKG
  [2] SDMMC1CKG — AXI master SDMMC1 clock gating disable
    values as EXTICKG
  [1] AHBMCKG — AXI master AHB clock gating disable
    values as EXTICKG
  [0] AXICKG — AXI interconnect matrix clock gating disable
    values as EXTICKG
